AUTOSAR XML (schema 4-0-3)
package /ComponentTypes
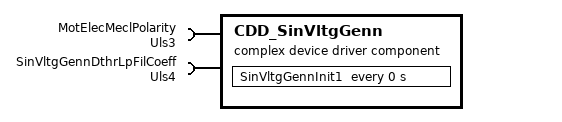
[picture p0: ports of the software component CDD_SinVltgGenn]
  complex device driver sw component type CDD_SinVltgGenn
    require port MotElecMeclPolarity: nonqueued-receiver-com-spec{data-element=Val, filter=data-filter-type=ALWAYS, init-value=1}, required-interface=Uls3
    require port SinVltgGennDthrLpFilCoeff: parameter-require-com-spec{init-value=0.625, parameter=Val}, required-interface=Uls4
    behavior CDD_SinVltgGenn_InternalBehavior: data-type-mapping=Nexteer
      ar-typed-per-instance-memorys:
        10 x data, all with sw-calibration-access=READ-ONLY:
          Fil1OutpPrev: type=Ti8
          Fil2OutpPrev: type=Ti8
          PhaDptOffsA: type=Ag3
          PhaDptOffsB: type=Ag3
          PhaDptOffsC: type=Ag3
          PhaOnTiSumAPrev: type=Ti9
          PhaOnTiSumBPrev: type=Ti9
          PhaOnTiSumCPrev: type=Ti9
          PwmPerdRng: type=Ti3
          RndNrPrev: type=Uls2
      timing event SinVltgGenn_InitEvent: start-on-event=SinVltgGennInit1, period=0
      runnable SinVltgGennInit1
        data-receive-point-by-arguments:
          access REC_MotElecMeclPolarity_Val: accessed-variable=MotElecMeclPolarity.Val
  swc implementation CDD_SinVltgGenn_Implementation: behavior=CDD_SinVltgGenn_InternalBehavior
    code-descriptors:
      code Default: artifact-descriptors=autosar-engineering-object={short-label=Default, category=SWSRC}
